# XN11EXXX register map
File version: 1.3
CPU: CM0 r0p0, little endian, no MPU, no FPU, 2 interrupt priority bits
Registers are 32-bit, read-write, reset 0x0 unless marked. A register's access mark holds for its fields unless they carry their own. Offsets are from the block's base; [hi:lo] are bit positions; {n}, {i} and the like mark numbered series; 'fields as' and 'values as' point back to an identical list.

## IOCON — I/O configuration block
Base 0x40044000
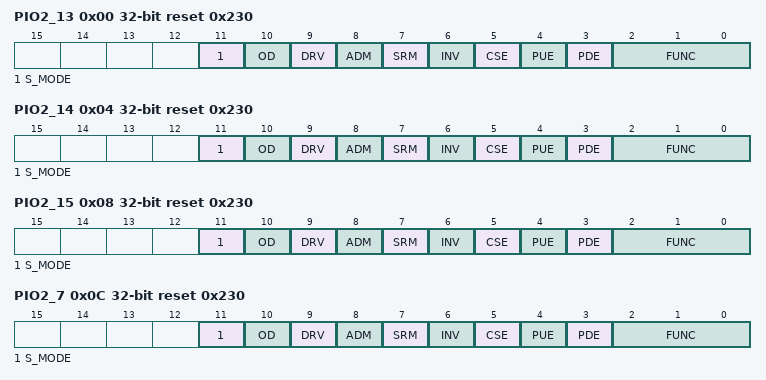
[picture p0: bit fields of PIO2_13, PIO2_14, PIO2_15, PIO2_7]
0x00 PIO2_13 reset 0x230 — Pin config register
  [11] S_MODE — Sample mode
  [10] OD — Open-drain mode
  [9] DRV — Drive current mode (Normal-drive pin)
  [8] ADM — Analog mode
  [7] SRM — Slew rate mode
  [6] INV — Invert input
  [5] CSE — Schmitt trigger enable
  [4] PUE — Pull-up mode
  [3] PDE — Pull-down mode
  [2:0] FUNC — Selects pin function
0x04 PIO2_14 reset 0x230 — Pin config register
  fields as PIO2_13
0x08 PIO2_15 reset 0x230 — Pin config register
  fields as PIO2_13
0x0C PIO2_7 reset 0x230 — Pin config register
  fields as PIO2_13
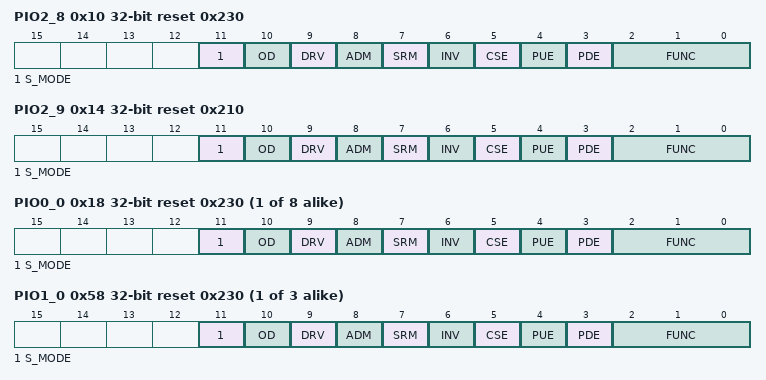
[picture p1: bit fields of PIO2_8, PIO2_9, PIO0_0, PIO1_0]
0x10 PIO2_8 reset 0x230 — Pin config register
  fields as PIO2_13
0x14 PIO2_9 reset 0x210 — Pin config register
  fields as PIO2_13
{0x18+4i} PIO0_{i} reset 0x230 (i=0..7) — Pin config register
  fields as PIO2_13
{0x58+4i} PIO1_{i} reset 0x230 (i=0..2) — Pin config register
  fields as PIO2_13
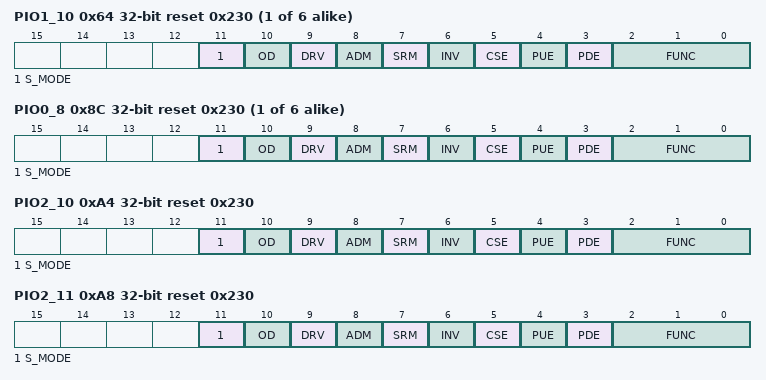
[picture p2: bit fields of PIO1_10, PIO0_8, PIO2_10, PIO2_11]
{0x3C+4i} PIO1_{i} reset 0x230 (i=10..15) — Pin config register
  fields as PIO2_13
{0x6C+4i} PIO0_{i} reset 0x230 (i=8..13) — Pin config register
  fields as PIO2_13
0xA4 PIO2_10 reset 0x230 — Pin config register
  fields as PIO2_13
0xA8 PIO2_11 reset 0x230 — Pin config register
  fields as PIO2_13
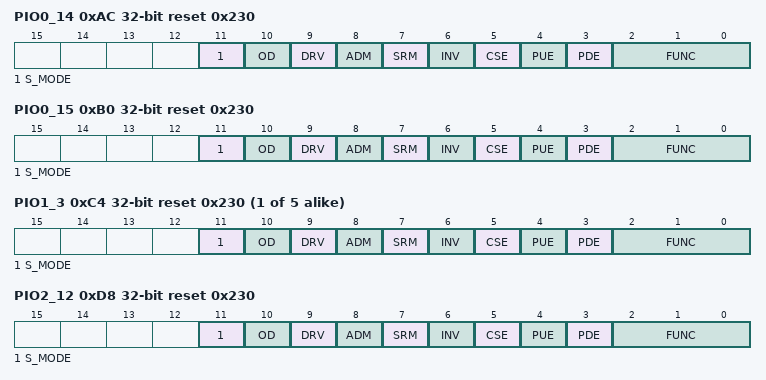
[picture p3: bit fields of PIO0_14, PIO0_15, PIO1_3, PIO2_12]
0xAC PIO0_14 reset 0x230 — Pin config register
  fields as PIO2_13
0xB0 PIO0_15 reset 0x230 — Pin config register
  fields as PIO2_13
{0xB8+4i} PIO1_{i} reset 0x230 (i=3..7) — Pin config register
  fields as PIO2_13
0xD8 PIO2_12 reset 0x230 — Pin config register
  fields as PIO2_13
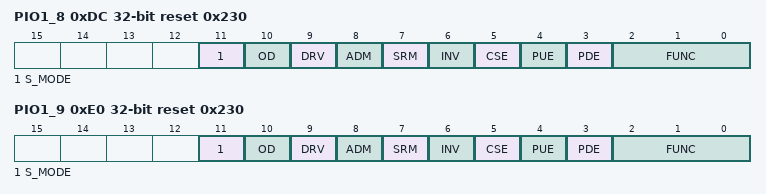
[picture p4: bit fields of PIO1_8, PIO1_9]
0xDC PIO1_8 reset 0x230 — Pin config register
  fields as PIO2_13
0xE0 PIO1_9 reset 0x230 — Pin config register
  fields as PIO2_13

## RTC — Real-time clock
Base 0x40050000
0x00 DR ro — RTC data register
0x04 MR — RTC match register
0x08 LR — RTC load register
0x0C CR — RTC control register
  [0] RTCSTART — Enables the RTC
0x10 ICSC — Interrupt control set/clear register
  [0] RTCIC — Interrupt control register
0x14 RIS ro — Raw interrupt status register
  [0] RTCRIS — Raw interrupt event flag register
0x18 MIS ro — Masked interrupt status register
  [0] RTCMIS — Masked interrupt register status
0x1C ICR wo — RTC interrupt clear register
  [0] RTCICR — Raw interrupt event flag clear register

## LCD — LCD driver
Base 0x40068000
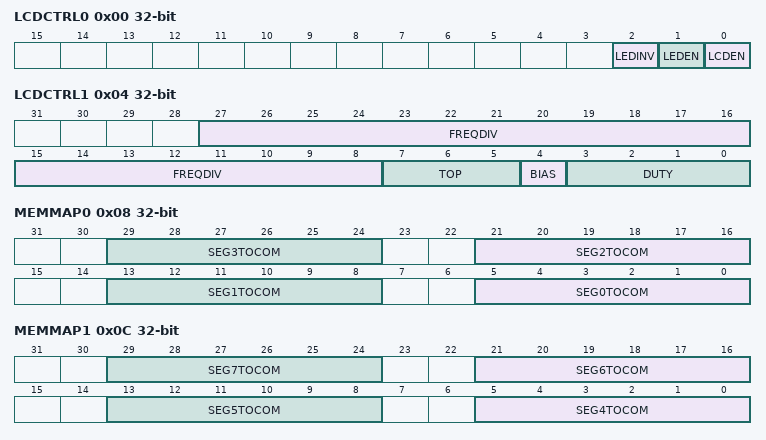
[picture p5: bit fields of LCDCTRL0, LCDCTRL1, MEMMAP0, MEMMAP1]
0x00 LCDCTRL0 — LCD driver enable
  [2] LEDINV — LED com output positive/negative selection
  [1] LEDEN — Enable LED driver
  [0] LCDEN — Enable LCD driver
0x04 LCDCTRL1 — LCD driver control register
  [27:8] FREQDIV — COM scan frequency divider
  [7:5] TOP — LCD output high voltage adjustment
  [4] BIAS — Bias voltage select
  [3:0] DUTY — Set LCD driver duty
0x08 MEMMAP0 — LCD data memory map0
  [8n+5:8n] SEG{n}TOCOM (n=0..3) — Segment {n} cross to Com0~5
0x0C MEMMAP1 — LCD driver data memory map1
  [8n-27:8n-32] SEG{n}TOCOM (n=4..7) — Segment {n} cross to Com0~5
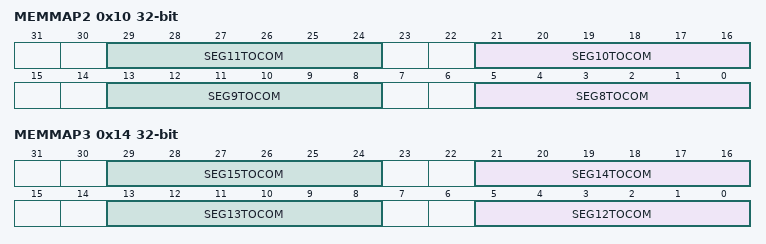
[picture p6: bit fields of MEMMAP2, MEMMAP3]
0x10 MEMMAP2 — LCD driver data memory map2
  [8n-59:8n-64] SEG{n}TOCOM (n=8..11) — Segment {n} cross to Com0~5
0x14 MEMMAP3 — LCD driver data memory map3
  [8n-91:8n-96] SEG{n}TOCOM (n=12..15) — Segment {n} cross to Com0~5
0x30 LCDOUTEN0 — LCD output enable 0
  [5:0] LCDCOMEN — Com0~5 output enable
0x34 LCDOUTEN1 — LCD output enable 1
  [15:0] LCDSEGEN — Segment 0~16 output enable

## CAPTOUCH — Capacitance Touch Sense
Base 0x40078000
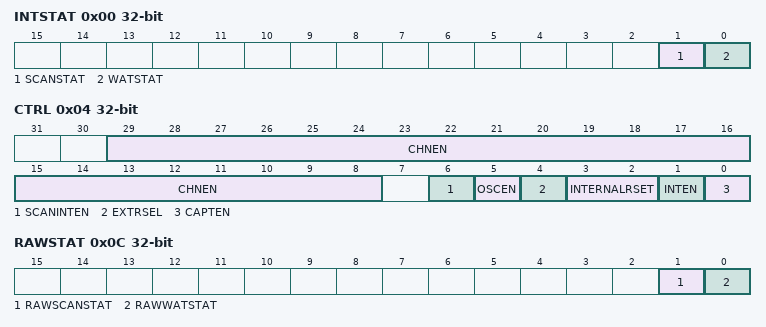
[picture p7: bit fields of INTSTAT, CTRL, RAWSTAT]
0x00 INTSTAT — Interrupt status register
  [1] SCANSTAT — Scan interrupt state flag
  [0] WATSTAT — Interrupt state flag trigger by water mark
0x04 CTRL — Cap Sense enable ctrl register
  [29:8] CHNEN — Touch pad channel enable
  [6] SCANINTEN — Enable interrupt at every time a pad scanned
  [5] OSCEN — Enable oscillator
  [4] EXTRSEL — Select internal resister or external resister
  [3:2] INTERNALRSET — Internal resister(frequency) select
  [1] INTEN — Touch pad interrupt enable
  [0] CAPTEN — Touch pad enable
0x08 SENSTM — Touchpad sense Time register
0x0C RAWSTAT — Interrupt status RAW register
  [1] RAWSCANSTAT — Scan interrupt raw state flag
  [0] RAWWATSTAT — Interrupt raw state flag trigger by water mark
0x10 WATMK — Interrupt watermark register
0x18 TOUCHCHN ro — Touched pad channel register
  [4:0] CHN — Touched pad channel number
0x1C TOUCHCNT ro — Touched pad count value register
0x20 SCANCHN ro — Scanned pad channel register
  [4:0] CHN — Last scanned pad channel number
0x24 SCANCNT ro — Scanned pad counter value register

## GPIO0 — General-purpose I/Os
Base 0x50000000
Same registers: GPIO1 0x50010000, GPIO2 0x50020000
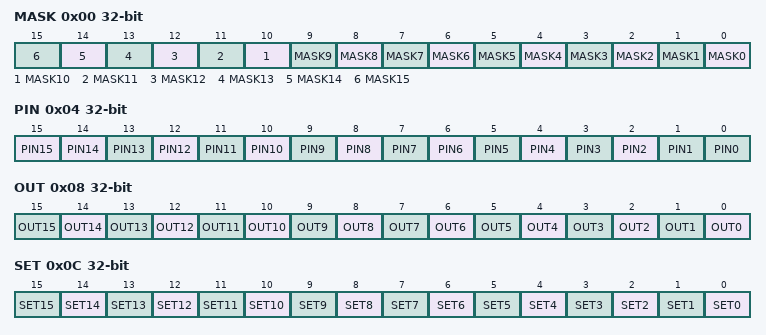
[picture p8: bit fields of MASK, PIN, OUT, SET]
0x00 MASK — Pin value mask register
  [n] MASK{n} (n=0..15) — GPIO pin PIOn_{n} access control bit
0x04 PIN ro — Pin state register
  [15] PIN15 — GPIO pin PIOn pin PIOn_15 PIN value
  [n] PIN{n} (n=1..14) — GPIO pin PIOn_{n} PIN value
  [0] PIN0 — GPIO pin PIOn pin PIOn_0 PIN value
0x08 OUT — Pin output value register
  [n] OUT{n} (n=0..15) — GPIO pin PIOn pin PIOn_{n} output value
0x0C SET wo — Pin output value set register
  [n] SET{n} (n=0..15) — Set GPIO pin PIOn_{n} output value
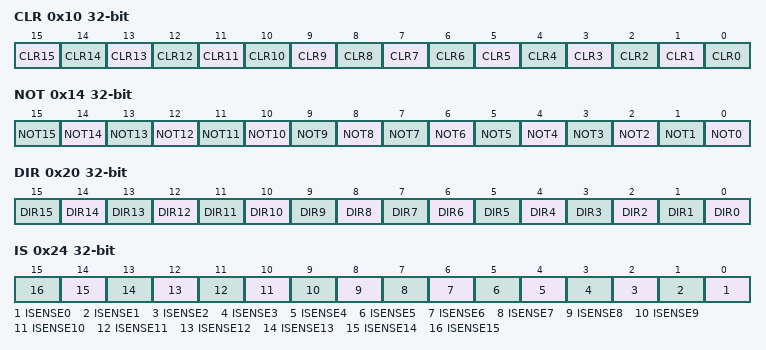
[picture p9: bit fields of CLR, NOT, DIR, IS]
0x10 CLR wo — Pin output value clear register
  [15] CLR15 — Clear GPIO pin PIOn_13 output value
  [n] CLR{n} (n=0..14) — Clear GPIO pin PIOn_{n} output value
0x14 NOT wo — Pin output value invert register
  [n] NOT{n} (n=0..15) — Invert GPIO pin PIOn_{n} output value
0x20 DIR — Data direction register
  [n] DIR{n} (n=0..15) — Selects GPIO pin PIOn_{n} as input or output
0x24 IS — interrupt sense register
  [n] ISENSE{n} (n=0..15) — Selects interrupt on pin PIOn_{n} as level or edge sensitive
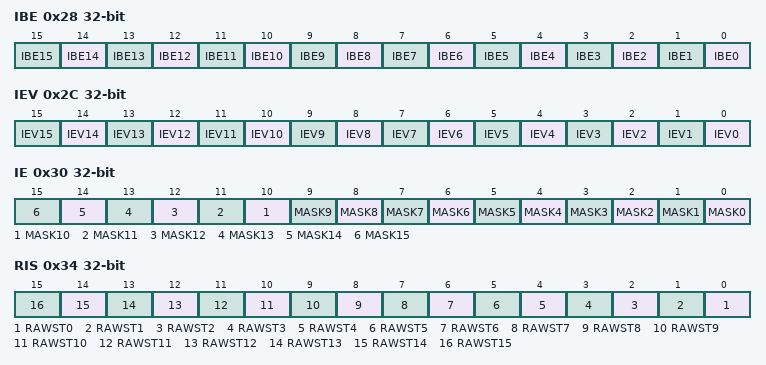
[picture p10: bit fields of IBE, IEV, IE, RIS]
0x28 IBE — Interrupt both edges register
  [n] IBE{n} (n=0..15) — Selects interrupt on pin PIOn_{n} to be triggered on both edges
0x2C IEV — Interrupt event register
  [n] IEV{n} (n=0..15) — Selects interrupt on pin PIOn_{n} to be triggered rising or falling edges.
0x30 IE — Interrupt mask register
  [n] MASK{n} (n=0..15) — Selects interrupt on pin PIOn_{n} to be masked.
0x34 RIS ro — Raw interrupt status register
  [n] RAWST{n} (n=0..15) — Raw interrupt status on pin PIOn_{n}
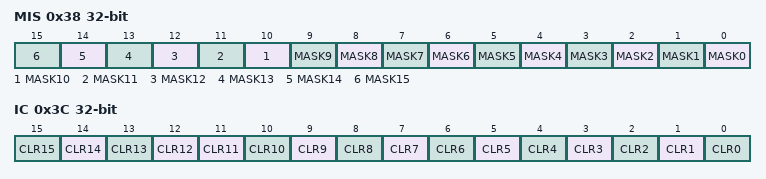
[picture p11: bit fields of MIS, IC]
0x38 MIS ro — Masked interrupt status register
  [n] MASK{n} (n=0..15) — Selects interrupt on pin PIOn_{n} to be masked
0x3C IC wo — Interrupt clear register
  [n] CLR{n} (n=12..15) — Selects interrupt on pin PIOn_{n} to be cleared
  [11] CLR11 — Selects interrupt on pin PIOn11 to be cleared
  [n] CLR{n} (n=0..10) — Selects interrupt on pin PIOn_{n} to be cleared

## FMC — Flash control block
Base 0x50060000
0x0C FLASH_RDCYC — Flash read cycle register
  [1:0] CYCLES — Flash read cycle time

## CRC — Micro digital signal processor
Base 0x50070000
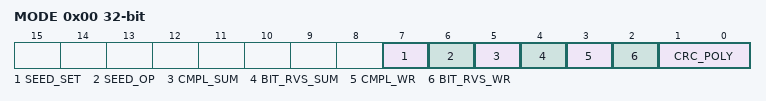
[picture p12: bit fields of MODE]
0x00 MODE — CRC mode register
  [7] SEED_SET — Write 1 to load seed to CRC generator
  [6] SEED_OP — CRC seed option set
  [5] CMPL_SUM — CRC sum complement
  [4] BIT_RVS_SUM — CRC sum bit order
  [3] CMPL_WR — Data complement
  [2] BIT_RVS_WR — Data bit order
  [1:0] CRC_POLY — CRC polynomial
0x04 SEED reset 0xFFFF — CRC seed register
0x08 SUM ro reset 0xFFFF — CRC checksum register
0x08 DATA wo reset 0xFFFF — CRC data register
